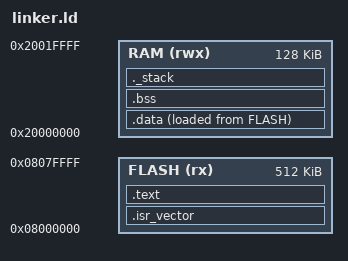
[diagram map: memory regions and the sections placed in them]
/* STM32F411CE/RE: 512 KB flash, 128 KB SRAM */

MEMORY
{
    FLASH (rx)  : ORIGIN = 0x08000000, LENGTH = 512K
    RAM   (rwx) : ORIGIN = 0x20000000, LENGTH = 128K
}

ENTRY(Reset_Handler)

SECTIONS
{
    .isr_vector :
    {
        KEEP(*(.isr_vector))
    } > FLASH

    .text :
    {
        *(.text*)
        *(.rodata*)
    } > FLASH

    _sidata = LOADADDR(.data);

    .data :
    {
        _sdata = .;
        *(.data*)
        _edata = .;
    } > RAM AT > FLASH

    .bss :
    {
        _sbss = .;
        *(.bss*)
        *(COMMON)
        _ebss = .;
    } > RAM

    ._stack :
    {
        . = ALIGN(8);
        . = . + 0x1000;
        . = ALIGN(8);
    } > RAM

    _estack = ORIGIN(RAM) + LENGTH(RAM);
}
